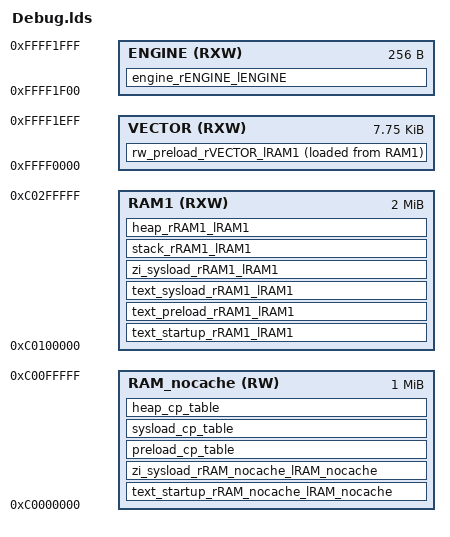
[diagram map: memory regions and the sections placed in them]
/* ld Linker Script - (Debug/Release) */
/* Auto generated by DJYOS lds Editor */
/* Mon Jun 17 16:16:04 CST 2013 */

MEMORY
{
	RAM_nocache(RW)		: org = 0xc0000000, len = 0x100000
	ENGINE(RXW)		: org = 0xffff1f00, len = 0x100
	RAM1(RXW)		: org = 0xc0100000, len = 2M
	VECTOR(RXW)		: org = 0xffff0000, len = 8k-0x100
}

SECTIONS
{
	
	. = ALIGN(0x08);
	text_startup_rRAM_nocache_lRAM_nocache :
	{
		./src/OS_code/bsp/arch/arm_common/mmucache.o (.mmutable)
	}>RAM_nocache 
	
	. = ALIGN(0x08);
	text_startup_rRAM1_lRAM1 :
	{
		./src/OS_code/bsp/arch/omapl138_arm/startup/*.o (.text .text.* .rodata .rodata.*)
		./src/OS_code/bsp/arch/omapl138_arm/core/*.o (.text .text.* .rodata .rodata.*)
		./src/OS_code/bsp/arch/arm_common/*.o (.text .text.* .rodata .rodata.*)
		./src/OS_code/loader/si/pre_loader.o (.text .text.* .rodata .rodata.*)
	}>RAM1 
	
	. = ALIGN(0x08);
	text_preload_rRAM1_lRAM1 :
	{
		KEEP(* (.table.exceptions .table.exceptions.*))
		KEEP(* (.table.vectors .table.vectors.*))
		./src/OS_code/loader/si/loader.o (.text .text.* .rodata .rodata.*)
		./src/OS_code/bsp/arch/omapl138_arm/core/*.o (.text .text.* .rodata .rodata.*)
		./src/OS_code/djyos/int/int.o (.text .text.* .rodata .rodata.*)
		./src/user/critical/*.o (.text .text.* .rodata .rodata.*)
		./src/OS_code/bsp/cpu_peripheral/src/omapl138_gpio.o (.text .text.* .rodata .rodata.*)
		./src/OS_code/bsp/cpu_peripheral/src/omapl138_peri.o (.text .text.* .rodata .rodata.*)
		./src/OS_code/loader/si/loader.o (.data .data.*)
		./src/OS_code/bsp/arch/omapl138_arm/core/*.o  (.data .data.*)
		./src/OS_code/djyos/int/int.o (.data .data.*)
		./src/user/critical/*.o (.data .data.*)
		./src/OS_code/bsp/cpu_peripheral/src/omapl138_gpio.o (.data .data.*)
		./src/OS_code/bsp/cpu_peripheral/src/omapl138_peri.o (.data .data.*)
		./src/OS_code/loader/si/loader.o (.bss .bss.* COMMON)
		./src/OS_code/bsp/arch/omapl138_arm/core/*.o (.bss .bss.* COMMON)
		./src/OS_code/djyos/int/int.o (.bss .bss.* COMMON)
		./src/user/critical/*.o (.bss .bss.* COMMON)
		./src/OS_code/bsp/cpu_peripheral/src/omapl138_gpio.o (.bss .bss.* COMMON)
		./src/OS_code/bsp/cpu_peripheral/src/omapl138_peri.o (.bss .bss.* COMMON)
	}>RAM1 
	
	. = ALIGN(0x08);
	rw_preload_rVECTOR_lRAM1 :
	{
		KEEP(* (.isr_vector .isr_vector.*))
	}>VECTOR AT>RAM1
	
	. = ALIGN(0x08);
	text_sysload_rRAM1_lRAM1 :
	{
		* (.text .text.* .rodata .rodata.*)
		* (.data .data.*)
	}>RAM1 
	
	. = ALIGN(0x08);
	zi_sysload_rRAM_nocache_lRAM_nocache (NOLOAD) :
	{
		./src/OS_code/bsp/board_peripheral/lcd/lcddrv.o(.bss.u8g_video_buffer)
	}>RAM_nocache 
	
	. = ALIGN(0x08);
	zi_sysload_rRAM1_lRAM1 (NOLOAD) :
	{
		* (.bss .bss.* COMMON)
	}>RAM1 
	
	. = ALIGN(0x08);
	preload_cp_table :
	{
		preload_copy_table = .;
		LONG(16)
		LONG(2)
		
		LONG(LOADADDR(text_preload_rRAM1_lRAM1))
		LONG(ADDR(text_preload_rRAM1_lRAM1))
		LONG(SIZEOF(text_preload_rRAM1_lRAM1))
		LONG(1)
		
		LONG(LOADADDR(rw_preload_rVECTOR_lRAM1))
		LONG(ADDR(rw_preload_rVECTOR_lRAM1))
		LONG(SIZEOF(rw_preload_rVECTOR_lRAM1))
		LONG(1)
	}>RAM_nocache 
	
	. = ALIGN(0x08);
	sysload_cp_table :
	{
		sysload_copy_table = .;
		LONG(16)
		LONG(3)
		
		LONG(LOADADDR(text_sysload_rRAM1_lRAM1))
		LONG(ADDR(text_sysload_rRAM1_lRAM1))
		LONG(SIZEOF(text_sysload_rRAM1_lRAM1))
		LONG(1)
		
		LONG(LOADADDR(zi_sysload_rRAM_nocache_lRAM_nocache))
		LONG(ADDR(zi_sysload_rRAM_nocache_lRAM_nocache))
		LONG(SIZEOF(zi_sysload_rRAM_nocache_lRAM_nocache))
		LONG(0)
		
		LONG(LOADADDR(zi_sysload_rRAM1_lRAM1))
		LONG(ADDR(zi_sysload_rRAM1_lRAM1))
		LONG(SIZEOF(zi_sysload_rRAM1_lRAM1))
		LONG(0)
	}>RAM_nocache 
	
	. = ALIGN(0x08);
	stack_rRAM1_lRAM1 (NOLOAD) :
	{
		usr_bottom = .;
		KEEP(* (.stack.usr .stack.usr.*))
		usr_top = ALIGN(0x08);
		
		svc_bottom = .;
		KEEP(* (.stack.svc .stack.svc.*))
		svc_top = ALIGN(0x08);
		
		irq_bottom = .;
		KEEP(* (.stack.irq .stack.irq.*))
		irq_top = ALIGN(0x08);
		
		fiq_bottom = .;
		KEEP(* (.stack.fiq .stack.fiq.*))
		fiq_top = ALIGN(0x08);
		
		undef_bottom = .;
		KEEP(* (.stack.undef .stack.undef.*))
		undef_top = ALIGN(0x08);
		
		abort_bottom = .;
		KEEP(* (.stack.abort .stack.abort.*))
		abort_top = ALIGN(0x08);
		
	}>RAM1 
	
	. = ALIGN(0x08);
	heap_rRAM1_lRAM1 (NOLOAD) :
	{
		sys_heap_bottom = .;
	}>RAM1 
	sys_heap_top = 0xc0100000+2M;
	
	. = ALIGN(0x08);
	heap_cp_table :
	{
		heap_copy_table = .;
		LONG(12)
		LONG(1)
		
		sys_heap_bottom_cnt = .;
		LONG(sys_heap_bottom)
		sys_heap_top_cnt = .;
		LONG(sys_heap_top)
	}>RAM_nocache 
	
	. = ALIGN(0x08);
	engine_rENGINE_lENGINE (NOLOAD) :
	{
		engine_irq = .;
		. += 0x04;
		engine_fiq = .;
		. += 0x04;
		engine_undef = .;
		. += 0x04;
		engine_swi = .;
		. += 0x04;
		engine_pabort = .;
		. += 0x04;
		engine_dabort = .;
		. += 0x04;
		engine_reserved = .;
		. += 0x04;
	}>ENGINE 
}
/**** The End ****/
